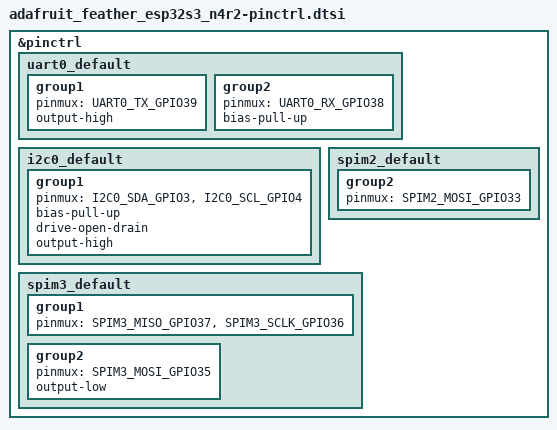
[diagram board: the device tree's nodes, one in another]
/*
 * Copyright (c) 2023 Helmut Lord
 *
 * SPDX-License-Identifier: Apache-2.0
 */

#include <zephyr/dt-bindings/pinctrl/esp-pinctrl-common.h>
#include <dt-bindings/pinctrl/esp32s3-pinctrl.h>
#include <zephyr/dt-bindings/pinctrl/esp32s3-gpio-sigmap.h>

&pinctrl {
	uart0_default: uart0_default {
		group1 {
			pinmux = <UART0_TX_GPIO39>;
			output-high;
		};
		group2 {
			pinmux = <UART0_RX_GPIO38>;
			bias-pull-up;
		};
	};

	i2c0_default: i2c0_default {
		group1 {
			pinmux = <I2C0_SDA_GPIO3>,
				 <I2C0_SCL_GPIO4>;
			bias-pull-up;
			drive-open-drain;
			output-high;
		};
	};

	spim2_default: spim2_default {
		group2 {
			pinmux = <SPIM2_MOSI_GPIO33>;
		};
	};

	spim3_default: spim3_default {
		group1 {
			pinmux = <SPIM3_MISO_GPIO37>,
				 <SPIM3_SCLK_GPIO36>;
		};
		group2 {
			pinmux = <SPIM3_MOSI_GPIO35>;
			output-low;
		};
	};

};
